# STM32F101C4T6 register map
File version: 1.0
Registers are 32-bit, access not given, reset 0x0 unless marked. A register's access mark holds for its fields unless they carry their own. Offsets are from the block's base; [hi:lo] are bit positions; {n}, {i} and the like mark numbered series.

## AFIO
Base 0x40010000
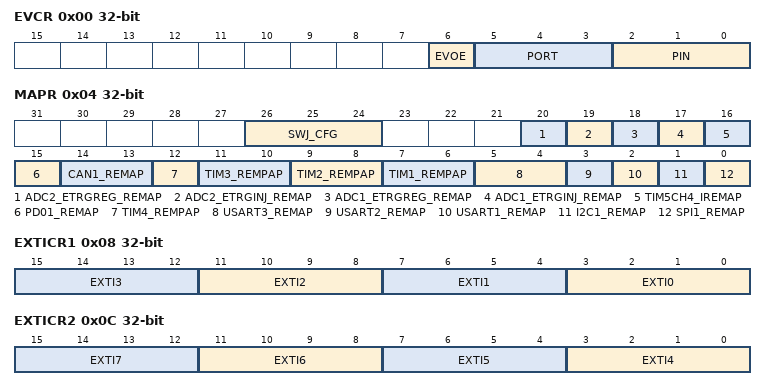
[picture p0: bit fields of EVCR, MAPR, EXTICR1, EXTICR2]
0x00 EVCR
  [6] EVOE, [5:3] PORT, [2:0] PIN
0x04 MAPR
  [26:24] SWJ_CFG, [20] ADC2_ETRGREG_REMAP, [19] ADC2_ETRGINJ_REMAP, [18] ADC1_ETRGREG_REMAP, [17] ADC1_ETRGINJ_REMAP, [16] TIM5CH4_IREMAP, [15] PD01_REMAP, [14:13] CAN1_REMAP, [12] TIM4_REMPAP, [11:10] TIM3_REMPAP, [9:8] TIM2_REMPAP, [7:6] TIM1_REMPAP, [5:4] USART3_REMAP, [3] USART2_REMAP, [2] USART1_REMAP, [1] I2C1_REMAP, [0] SPI1_REMAP
0x08 EXTICR1
  [4n+3:4n] EXTI{n} (n=0..3)
0x0C EXTICR2
  [4n-13:4n-16] EXTI{n} (n=4..7)
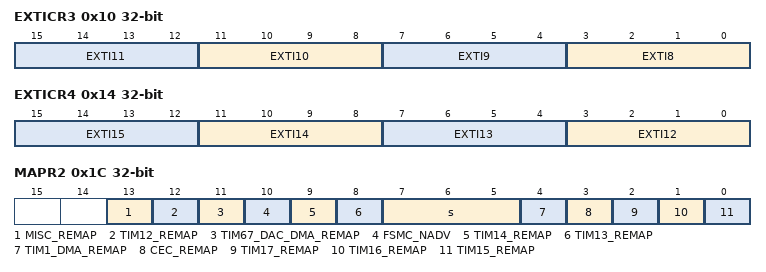
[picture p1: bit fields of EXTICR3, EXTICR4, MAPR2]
0x10 EXTICR3
  [4n-29:4n-32] EXTI{n} (n=8..11)
0x14 EXTICR4
  [4n-45:4n-48] EXTI{n} (n=12..15)
0x1C MAPR2
  [13] MISC_REMAP, [12] TIM12_REMAP, [11] TIM67_DAC_DMA_REMAP, [10] FSMC_NADV, [9] TIM14_REMAP, [8] TIM13_REMAP, [7:5] s, [4] TIM1_DMA_REMAP, [3] CEC_REMAP, [2] TIM17_REMAP, [1] TIM16_REMAP, [0] TIM15_REMAP

## EXTI
Base 0x40010400
0x00 IMR
  [19:0] MR
0x04 EMR
  [19:0] MR
0x08 RTSR
  [19:0] TR
0x0C FTSR
  [19:0] TR
0x10 SWIER
  [19:0] SWIER
0x14 PR
  [19:0] PR

## GPIOA
Base 0x40010800
Same registers: GPIOB 0x40010C00, GPIOC 0x40011000, GPIOD 0x40011400, GPIOE 0x40011800, GPIOF 0x40011C00, GPIOG 0x40012000
0x00 CRL
0x04 CRH
0x08 IDR
0x0C ODR
0x10 BSRR
0x14 BRR
0x18 LCKR

## ADC1
Base 0x40012400
Same registers: ADC3 0x40013C00
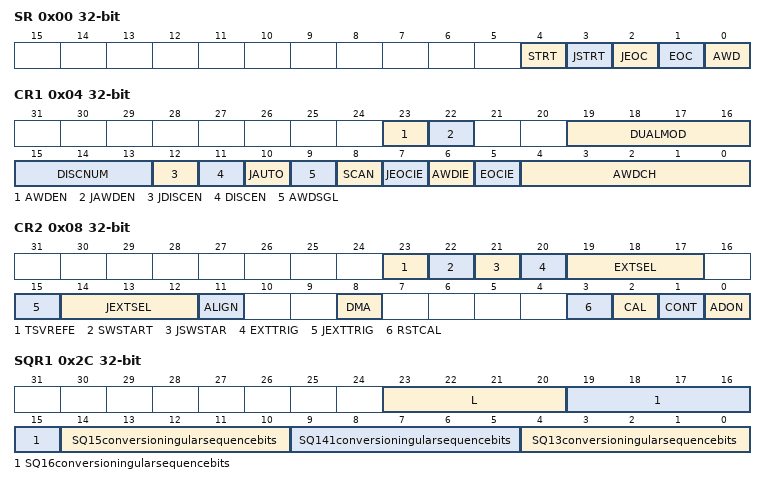
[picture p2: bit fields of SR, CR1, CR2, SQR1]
0x00 SR
  [4] STRT, [3] JSTRT, [2] JEOC, [1] EOC, [0] AWD
0x04 CR1
  [23] AWDEN, [22] JAWDEN, [19:16] DUALMOD, [15:13] DISCNUM, [12] JDISCEN, [11] DISCEN, [10] JAUTO, [9] AWDSGL, [8] SCAN, [7] JEOCIE, [6] AWDIE, [5] EOCIE, [4:0] AWDCH
0x08 CR2
  [23] TSVREFE, [22] SWSTART, [21] JSWSTAR, [20] EXTTRIG, [19:17] EXTSEL, [15] JEXTTRIG, [14:12] JEXTSEL, [11] ALIGN, [8] DMA, [3] RSTCAL, [2] CAL, [1] CONT, [0] ADON
0x0C SMPR1
  [31:0] SMP
0x10 SMPR2
  [31:0] SMP
{0x10+4i} JOFR{i} (i=1..4)
  [11:0] JOFFSET{i}
0x24 HTR
  [11:0] HT
0x28 LTR
  [11:0] LT
0x2C SQR1
  [23:20] L, [19:15] SQ16conversioningularsequencebits, [14:10] SQ15conversioningularsequencebits, [9:5] SQ141conversioningularsequencebits, [4:0] SQ13conversioningularsequencebits
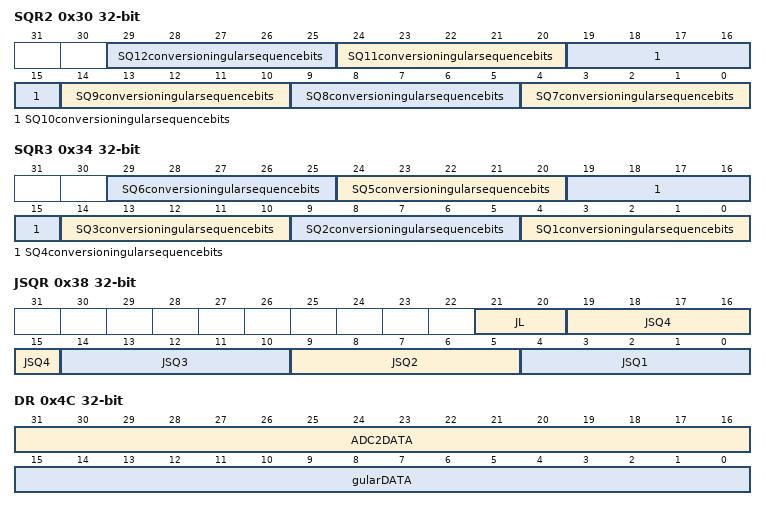
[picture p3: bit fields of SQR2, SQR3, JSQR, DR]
0x30 SQR2
  [5n-31:5n-35] SQ{n}conversioningularsequencebits (n=7..12)
0x34 SQR3
  [5n-1:5n-5] SQ{n}conversioningularsequencebits (n=1..6)
0x38 JSQR
  [21:20] JL, [5n-1:5n-5] JSQ{n} (n=1..4)
{0x38+4i} JDR{i} (i=1..4)
  [15:0] JDATA
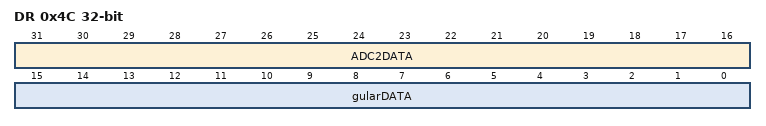
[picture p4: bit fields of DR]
0x4C DR
  [31:16] ADC2DATA, [15:0] gularDATA

## ADC2
Base 0x40012800
Registers as ADC1; these are added or differ:
0x4C DR
  [31:16] ADC2DATA, [15:0] gularDATA

## SDIO
Base 0x40018000
0x00 POWER
  [1:0] PWRCTRL
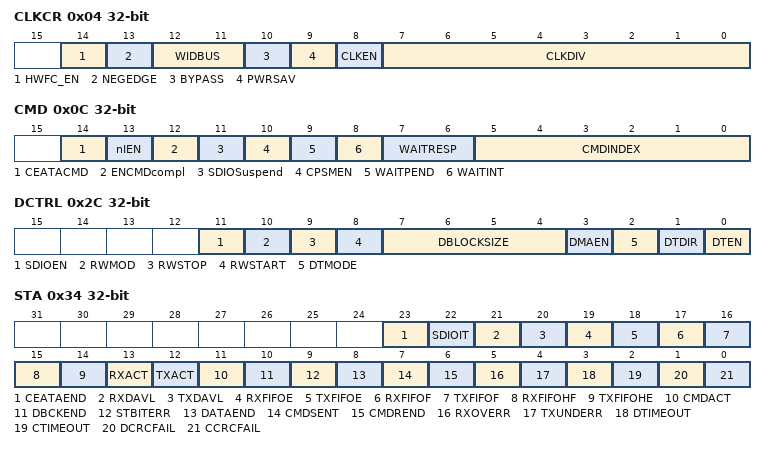
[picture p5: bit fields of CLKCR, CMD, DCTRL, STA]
0x04 CLKCR
  [14] HWFC_EN, [13] NEGEDGE, [12:11] WIDBUS, [10] BYPASS, [9] PWRSAV, [8] CLKEN, [7:0] CLKDIV
0x08 ARG
  [31:0] CMDARG
0x0C CMD
  [14] CEATACMD, [13] nIEN, [12] ENCMDcompl, [11] SDIOSuspend, [10] CPSMEN, [9] WAITPEND, [8] WAITINT, [7:6] WAITRESP, [5:0] CMDINDEX
0x10 RESPCMD
  [5:0] RESPCMD
{0x10+4i} RESP{i} (i=1..4)
  [31:0] CARDSTATUS{i}
0x24 DTIMER
  [31:0] DATATIME
0x28 DLEN
  [24:0] DATALENGTH
0x2C DCTRL
  [11] SDIOEN, [10] RWMOD, [9] RWSTOP, [8] RWSTART, [7:4] DBLOCKSIZE, [3] DMAEN, [2] DTMODE, [1] DTDIR, [0] DTEN
0x30 DCOUNT
  [24:0] DATACOUNT
0x34 STA
  [23] CEATAEND, [22] SDIOIT, [21] RXDAVL, [20] TXDAVL, [19] RXFIFOE, [18] TXFIFOE, [17] RXFIFOF, [16] TXFIFOF, [15] RXFIFOHF, [14] TXFIFOHE, [13] RXACT, [12] TXACT, [11] CMDACT, [10] DBCKEND, [9] STBITERR, [8] DATAEND, [7] CMDSENT, [6] CMDREND, [5] RXOVERR, [4] TXUNDERR, [3] DTIMEOUT, [2] CTIMEOUT, [1] DCRCFAIL, [0] CCRCFAIL
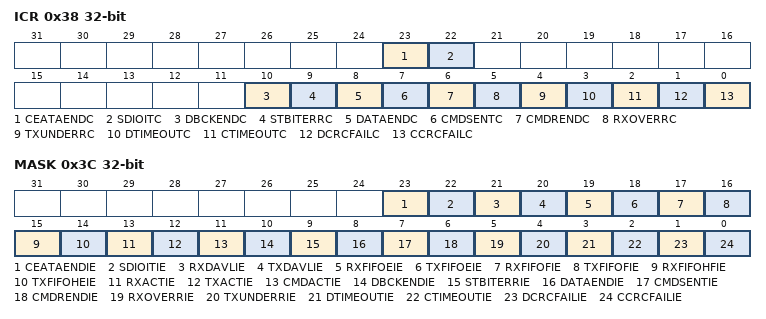
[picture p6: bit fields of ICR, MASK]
0x38 ICR
  [23] CEATAENDC, [22] SDIOITC, [10] DBCKENDC, [9] STBITERRC, [8] DATAENDC, [7] CMDSENTC, [6] CMDRENDC, [5] RXOVERRC, [4] TXUNDERRC, [3] DTIMEOUTC, [2] CTIMEOUTC, [1] DCRCFAILC, [0] CCRCFAILC
0x3C MASK
  [23] CEATAENDIE, [22] SDIOITIE, [21] RXDAVLIE, [20] TXDAVLIE, [19] RXFIFOEIE, [18] TXFIFOEIE, [17] RXFIFOFIE, [16] TXFIFOFIE, [15] RXFIFOHFIE, [14] TXFIFOHEIE, [13] RXACTIE, [12] TXACTIE, [11] CMDACTIE, [10] DBCKENDIE, [9] STBITERRIE, [8] DATAENDIE, [7] CMDSENTIE, [6] CMDRENDIE, [5] RXOVERRIE, [4] TXUNDERRIE, [3] DTIMEOUTIE, [2] CTIMEOUTIE, [1] DCRCFAILIE, [0] CCRCFAILIE
0x48 FIFOCNT
  [23:0] FIFOCOUNT
0x80 FIFO
  [31:0] FIF0Data
